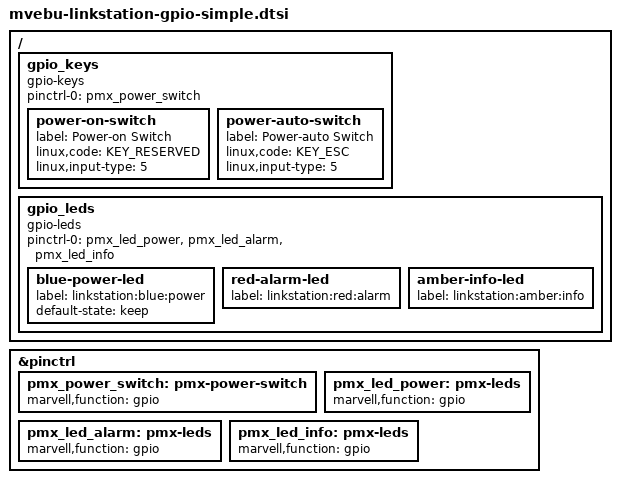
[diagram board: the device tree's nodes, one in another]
/*
 * Device Tree common file for gpio-{keys,leds} on Buffalo Linkstation
 *
 * Copyright (C) 2015, 2016
 * Roger Shimizu <rogershimizu@gmail.com>
 *
 * This file is dual-licensed: you can use it either under the terms
 * of the GPL or the X11 license, at your option. Note that this dual
 * licensing only applies to this file, and not this project as a
 * whole.
 *
 *  a) This file is free software; you can redistribute it and/or
 *     modify it under the terms of the GNU General Public License as
 *     published by the Free Software Foundation; either version 2 of the
 *     License, or (at your option) any later version.
 *
 *     This file is distributed in the hope that it will be useful,
 *     but WITHOUT ANY WARRANTY; without even the implied warranty of
 *     MERCHANTABILITY or FITNESS FOR A PARTICULAR PURPOSE.  See the
 *     GNU General Public License for more details.
 *
 * Or, alternatively,
 *
 *  b) Permission is hereby granted, free of charge, to any person
 *     obtaining a copy of this software and associated documentation
 *     files (the "Software"), to deal in the Software without
 *     restriction, including without limitation the rights to use,
 *     copy, modify, merge, publish, distribute, sublicense, and/or
 *     sell copies of the Software, and to permit persons to whom the
 *     Software is furnished to do so, subject to the following
 *     conditions:
 *
 *     The above copyright notice and this permission notice shall be
 *     included in all copies or substantial portions of the Software.
 *
 *     THE SOFTWARE IS PROVIDED "AS IS", WITHOUT WARRANTY OF ANY KIND,
 *     EXPRESS OR IMPLIED, INCLUDING BUT NOT LIMITED TO THE WARRANTIES
 *     OF MERCHANTABILITY, FITNESS FOR A PARTICULAR PURPOSE AND
 *     NONINFRINGEMENT. IN NO EVENT SHALL THE AUTHORS OR COPYRIGHT
 *     HOLDERS BE LIABLE FOR ANY CLAIM, DAMAGES OR OTHER LIABILITY,
 *     WHETHER IN AN ACTION OF CONTRACT, TORT OR OTHERWISE, ARISING
 *     FROM, OUT OF OR IN CONNECTION WITH THE SOFTWARE OR THE USE OR
 *     OTHER DEALINGS IN THE SOFTWARE.
 */

#include <dt-bindings/input/input.h>

/ {
	gpio_keys {
		compatible = "gpio-keys";
		#address-cells = <1>;
		#size-cells = <0>;
		pinctrl-0 = <&pmx_power_switch>;
		pinctrl-names = "default";

		power-on-switch {
			label = "Power-on Switch";
			linux,code = <KEY_RESERVED>;
			linux,input-type = <5>;
		};

		power-auto-switch {
			label = "Power-auto Switch";
			linux,code = <KEY_ESC>;
			linux,input-type = <5>;
		};
	};

	gpio_leds {
		compatible = "gpio-leds";
		pinctrl-0 = <&pmx_led_power &pmx_led_alarm &pmx_led_info>;
		pinctrl-names = "default";

		blue-power-led {
			label = "linkstation:blue:power";
			default-state = "keep";
		};

		red-alarm-led {
			label = "linkstation:red:alarm";
		};

		amber-info-led {
			label = "linkstation:amber:info";
		};
	};
};

&pinctrl {
	pmx_power_switch: pmx-power-switch {
		marvell,function = "gpio";
	};

	pmx_led_power: pmx-leds {
		marvell,function = "gpio";
	};

	pmx_led_alarm: pmx-leds {
		marvell,function = "gpio";
	};

	pmx_led_info: pmx-leds {
		marvell,function = "gpio";
	};
};
